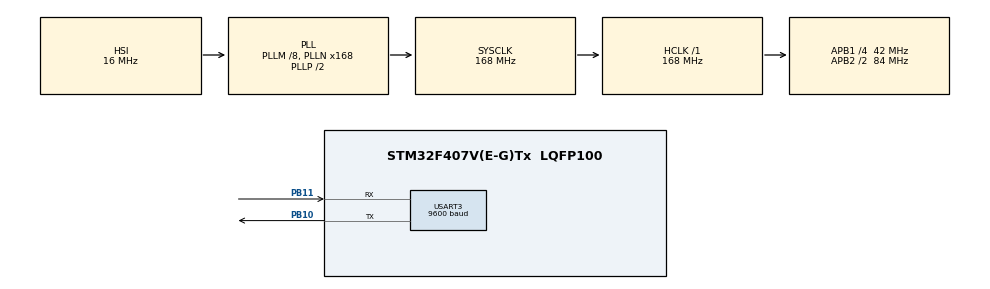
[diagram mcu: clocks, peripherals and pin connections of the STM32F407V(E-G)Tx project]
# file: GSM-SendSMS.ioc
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Mcu.Family=STM32F4
Mcu.Name=STM32F407V(E-G)Tx
Mcu.Package=LQFP100
NVIC.PriorityGroup=NVIC_PRIORITYGROUP_4
PB10.Mode=Asynchronous
PB10.Signal=USART3_TX
PB11.Mode=Asynchronous
PB11.Signal=USART3_RX
ProjectManager.HeapSize=0x200
ProjectManager.StackSize=0x400
ProjectManager.TargetToolchain=MDK-ARM V5.27
RCC.48MHZClocksFreq_Value=84000000
RCC.AHBFreq_Value=168000000
RCC.APB1CLKDivider=RCC_HCLK_DIV4
RCC.APB1Freq_Value=42000000
RCC.APB1TimFreq_Value=84000000
RCC.APB2CLKDivider=RCC_HCLK_DIV2
RCC.APB2Freq_Value=84000000
RCC.APB2TimFreq_Value=168000000
RCC.CortexFreq_Value=168000000
RCC.HCLKFreq_Value=168000000
RCC.HSE_VALUE=25000000
RCC.HSI_VALUE=16000000
RCC.LSE_VALUE=32768
RCC.PLLM=8
RCC.PLLN=168
RCC.SYSCLKFreq_VALUE=168000000
RCC.SYSCLKSource=RCC_SYSCLKSOURCE_PLLCLK
RCC.VCOOutputFreq_Value=336000000
USART3.BaudRate=9600
USART3.VirtualMode=VM_ASYNC
board=custom

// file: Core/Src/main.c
/* USER CODE BEGIN Header */
/**
  ******************************************************************************
  * @file           : main.c
  * @brief          : Main program body
  ******************************************************************************
  * @attention
  *
  * <h2><center>&copy; Copyright (c) 2024 STMicroelectronics.
  * All rights reserved.</center></h2>
  *
  * This software component is licensed by ST under BSD 3-Clause license,
  * the "License"; You may not use this file except in compliance with the
  * License. You may obtain a copy of the License at:
  *                        opensource.org/licenses/BSD-3-Clause
  *
  ******************************************************************************
  */
/* USER CODE END Header */
#include "main.h"
#include "usart.h"
#include "gpio.h"

/* USER CODE BEGIN Includes */
#include <stdio.h>
#include <stdarg.h>
#include <string.h>
/* USER CODE END Includes */

/* USER CODE BEGIN PV */
static const char PHONE[]   = "+989379878489";
static const char MESSAGE[] = "This is From STM407";

/* USER CODE END PV */

void SystemClock_Config(void);
/* USER CODE BEGIN PFP */
void GSM_sendSms(const char* phone, const char* message);
int16_t GSM_checkResult(void);

void GSM_sendStr(char* str);
void GSM_sendFmt(const char* fmt, ...);
void GSM_sendByte(uint8_t byte);
/* USER CODE END PFP */

int main(void)
{

  /* MCU Configuration--------------------------------------------------------*/

  /* Reset of all peripherals, Initializes the Flash interface and the Systick. */
  HAL_Init();

  /* Configure the system clock */
  SystemClock_Config();

  /* Initialize all configured peripherals */
  MX_GPIO_Init();
  MX_USART3_UART_Init();

  /* Infinite loop */
  /* USER CODE BEGIN WHILE */
  // Wait for GSM Module connect to Network
  HAL_Delay(1000);
  GSM_sendSms(PHONE, MESSAGE);
  while (1)
  {
    /* USER CODE END WHILE */

  }
}

void SystemClock_Config(void)
{
  RCC_OscInitTypeDef RCC_OscInitStruct = {0};
  RCC_ClkInitTypeDef RCC_ClkInitStruct = {0};

  /** Configure the main internal regulator output voltage
  */
  __HAL_RCC_PWR_CLK_ENABLE();
  __HAL_PWR_VOLTAGESCALING_CONFIG(PWR_REGULATOR_VOLTAGE_SCALE1);
  /** Initializes the RCC Oscillators according to the specified parameters
  * in the RCC_OscInitTypeDef structure.
  */
  RCC_OscInitStruct.OscillatorType = RCC_OSCILLATORTYPE_HSI;
  RCC_OscInitStruct.HSIState = RCC_HSI_ON;
  RCC_OscInitStruct.HSICalibrationValue = RCC_HSICALIBRATION_DEFAULT;
  RCC_OscInitStruct.PLL.PLLState = RCC_PLL_ON;
  RCC_OscInitStruct.PLL.PLLSource = RCC_PLLSOURCE_HSI;
  RCC_OscInitStruct.PLL.PLLM = 8;
  RCC_OscInitStruct.PLL.PLLN = 168;
  RCC_OscInitStruct.PLL.PLLP = RCC_PLLP_DIV2;
  RCC_OscInitStruct.PLL.PLLQ = 4;
  if (HAL_RCC_OscConfig(&RCC_OscInitStruct) != HAL_OK)
  {
    Error_Handler();
  }
  /** Initializes the CPU, AHB and APB buses clocks
  */
  RCC_ClkInitStruct.ClockType = RCC_CLOCKTYPE_HCLK|RCC_CLOCKTYPE_SYSCLK
                              |RCC_CLOCKTYPE_PCLK1|RCC_CLOCKTYPE_PCLK2;
  RCC_ClkInitStruct.SYSCLKSource = RCC_SYSCLKSOURCE_PLLCLK;
  RCC_ClkInitStruct.AHBCLKDivider = RCC_SYSCLK_DIV1;
  RCC_ClkInitStruct.APB1CLKDivider = RCC_HCLK_DIV4;
  RCC_ClkInitStruct.APB2CLKDivider = RCC_HCLK_DIV2;

  if (HAL_RCC_ClockConfig(&RCC_ClkInitStruct, FLASH_LATENCY_5) != HAL_OK)
  {
    Error_Handler();
  }
}

/* USER CODE BEGIN 4 */
void GSM_sendSms(const char* phone, const char* message) {
  // Check Connection
  GSM_sendStr("AT\r\n");
  HAL_Delay(250);
  // Check Connection
  GSM_sendStr("AT\r\n");
  if (GSM_checkResult() == 0) {
    // Echo Off
    GSM_sendStr("ATE0\r\n");
    if (GSM_checkResult() == 0) {
      // Set Text Mode
      GSM_sendStr("AT+CMGF=1\r\n");
      if (GSM_checkResult() == 0) {
        // Set SMS Config
        GSM_sendStr("AT+CSMP=17,167,0,0\r\n");
        if (GSM_checkResult() == 0) {
          // Send SMS Phone
          GSM_sendFmt("AT+CMGS=\"%s\"\r\n", phone);
          // Wait for "> "
          HAL_Delay(50);
          // Send Message
          GSM_sendStr((char*) message);
          // Send Ctrl-Z (0x1A)
          GSM_sendByte(0x1A);
          GSM_checkResult();
        }
      }
    }
  }
}

int16_t GSM_checkResult(void) {
  char buf[64] = {0};
  uint16_t len = 0;

  HAL_UARTEx_ReceiveToIdle(&huart3, (uint8_t*) buf, sizeof(buf), &len, 1000);

  if (len > 0) {
    buf[len] = '\0';
    // Process
    if (strstr(buf, "OK") != 0) {
      return 0;
    }
    else {
      HAL_Delay(50);
      return 1;
    }
  }
  else {
    // Nothing received
    HAL_Delay(50);
    return -1;
  }
}

void GSM_sendStr(char* str) {
  uint16_t len = strlen(str);
  HAL_UART_Transmit(&huart3, (uint8_t*) str, len, len + 1);
}
void GSM_sendFmt(const char* fmt, ...) {
  char buf[128];
  va_list args;
  va_start(args, fmt);
  uint32_t len = vsnprintf(buf, sizeof(buf), fmt, args);
  va_end(args);

  HAL_UART_Transmit(&huart3, (uint8_t*) buf, len, len + 1);
}
void GSM_sendByte(uint8_t byte) {
  HAL_UART_Transmit(&huart3, &byte, sizeof(byte), sizeof(byte));
}
/* USER CODE END 4 */

void Error_Handler(void)
{
  __disable_irq();
  while (1)
  {
  }
}

/************************ (C) COPYRIGHT STMicroelectronics *****END OF FILE****/
